AUTOSAR XML (schema 4-2-2)
package /AUTOSAR/Components
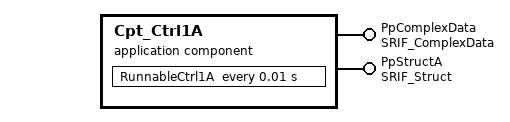
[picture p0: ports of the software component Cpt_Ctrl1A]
  application sw component type Cpt_Ctrl1A
    provide port PpComplexData: provided-interface=SRIF_ComplexData
    provide port PpStructA: provided-interface=SRIF_Struct
    behavior IbCtrl
      timing event timingEvent_10: start-on-event=RunnableCtrl1A, period=0.01
      runnable RunnableCtrl1A: symbol=AppRunnableCtrl1A
        data-write-access:
          5 x access:
            dataWriteAccess_Primitive: accessed-variable=PpComplexData.dataElementPrimitive
            dataWriteAccess_Array: accessed-variable=PpComplexData.dataElementArray
            dataWriteAccess_Struct: accessed-variable=PpComplexData.dataElementStruct
            dataWriteAccess_StructArray: accessed-variable=PpComplexData.dataElementStructArray
            dataWriteAccess_StructA: accessed-variable=PpStructA.dataElementsStructA
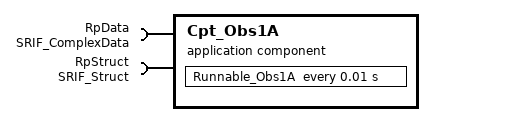
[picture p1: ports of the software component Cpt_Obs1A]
  application sw component type Cpt_Obs1A
    require port RpData: required-interface=SRIF_ComplexData
      required-com-specs:
        data-element=dataElementPrimitive, external-replacement=dataElementPrimitive, init-value=0
        data-element=dataElementStruct, init-value=fields=[0, 1, 2]
        data-element=dataElementArray, init-value=[0]
        data-element=dataElementStructArray, init-value=fields=[0]
    require port RpStruct: nonqueued-receiver-com-spec{data-element=dataElementsStructA, init-value=fields=[0, 0, 0, 0]}, required-interface=SRIF_Struct
    behavior IbObs
      timing event timingEvent_10: start-on-event=Runnable_Obs1A, period=0.01
      runnable Runnable_Obs1A: symbol=AppRunnable_Obs1A
        data-read-access:
          5 x access:
            dataReadAccess_Primitive: accessed-variable=RpData.dataElementPrimitive
            dataReadAccess_Array: accessed-variable=RpData.dataElementArray
            dataReadAccess_Struct: accessed-variable=RpData.dataElementStruct
            dataReadAccess_StructArray: accessed-variable=RpData.dataElementStructArray
            dataReadAccess_StructA: accessed-variable=RpStruct.dataElementsStructA
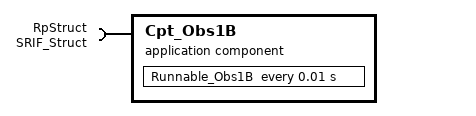
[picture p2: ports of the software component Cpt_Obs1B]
  application sw component type Cpt_Obs1B
    require port RpStruct: nonqueued-receiver-com-spec{data-element=dataElementsStructA, init-value=fields=[0, 1, 2, 0]}, required-interface=SRIF_Struct
    behavior IbObs1B
      timing event timingEvent_10: start-on-event=Runnable_Obs1B, period=0.01
      runnable Runnable_Obs1B: symbol=AppRunnable_Obs1B
        data-read-access:
          access dataReadAccess_StructA: accessed-variable=RpStruct.dataElementsStructA
